# PAC52XX register map
Vendor: Active-Semi; Series: PAC52XX; File version: 1.0
CPU: CM0 r0p0, little endian, no MPU, no FPU, vendor SysTick, 2 interrupt priority bits
Registers are 32-bit, read-write, reset 0x0 unless marked. A register's access mark holds for its fields unless they carry their own. Offsets are from the block's base; [hi:lo] are bit positions.

## I2C
Base 0x401B0000
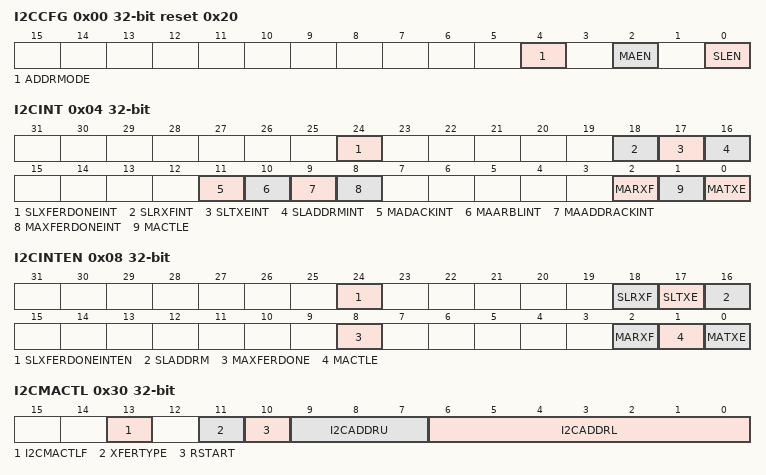
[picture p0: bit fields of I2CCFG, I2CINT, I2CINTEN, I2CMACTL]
0x00 I2CCFG reset 0x20 — I2C Configuration Register
  [4] ADDRMODE — Address Mode
    0=7-bit addressing; 1=10-bit addressing
  [2] MAEN — Master Enable
    0=disable (I2C master disable); 1=enable (I2C Master enable)
  [0] SLEN — Slave Enable
    0=disable (I2C Slave disable); 1=enable (I2C Slave enable)
0x04 I2CINT ro — I2C Interrupt
  [24] SLXFERDONEINT — Slave transfer done interrupt
    0=false (Slave transfer not completed); 1=true (Slave transfer complete, cleared on read)
  [18] SLRXFINT — Slave receive data register SLRXDATA full
    0=false (SLRXDATA did not receive data since last read of I2CINT); 1=true (SLRXDATA received data from I2C bus, cleared on read)
  [17] SLTXEINT — Slave transmit data register SLTXDATA empty
    0=false (SLTXDATA not transmitted since last read of I2CINT); 1=true (SLTXDATA transmitted to I2C bus, cleared on read)
  [16] SLADDRMINT — Slave address match
    0=none (no match); 1=match (Slave address match detected, cleared on read)
  [11] MADACKINT — Master data acknowledge
    0=ACK (Master data ACK'd); 1=NACK (Master data NACK'd, cleared on read)
  [10] MAARBLINT — Master lost arbitration
    0=false (no error); 1=true (Master lost arbitration, clear on read)
  [9] MAADDRACKINT — Master address acknowledged
    0=ACK (Master address ACK'd); 1=NACK (Master address NACK'd, cleared on read)
  [8] MAXFERDONEINT — Master transfer complete
    0=false (not done); 1=true (Master transfer complete, cleared on read)
  [2] MARXF — Master receive data register MARXDATA full
    0=false (MARXDATA did not receive data since last read of I2CINT); 1=true (MARXDATA received data from I2C bus, cleared on read)
  [1] MACTLE — MACCTL access register accessed
    0=false (I2CMACTL not accessed by I2C engine since last read of I2CINT); 1=true (I2CMACTL processed by I2C engine, clears on read)
  [0] MATXE — Master transmit data register MATXDATA empty
    0=not transmitted (MATXDATA not transmitted since last read of I2CINT); 1=transmitted (MATXDATA transmitted to I2C bus, clears on read)
0x08 I2CINTEN — I2C Interrupt Enable
  [all] fields
    0=disabled (interrupt disabled); 1=enabled (interrupt enabled)
  [24] SLXFERDONEINTEN — SLXFERDONEINTEN interrupt enable
  [18] SLRXF — SLRXF interrupt enable
  [17] SLTXE — SLTXE interrupt enable
  [16] SLADDRM — SLADDRM interrupt enable
  [8] MAXFERDONE — MAXFERDONE interrupt enable
  [2] MARXF — MARXF interrupt enable
  [1] MACTLE — MACTLE interrupt enable
  [0] MATXE — MATXE interrupt enable
0x30 I2CMACTL — I2C master access control
  [13] I2CMACTLF — I2CMACTL full
    0=not full (I2CMACTL processed, write allowed); 1=full (I2CMACTL full, write not allowed, cleared on read)
  [11] XFERTYPE — Master transfer type
    0=write (I2C Master write); 1=read (I2C Master read)
  [10] RSTART — Repeated start
    0=no (STOP at end of transfer); 1=yes (No STOP at end of transfer, repeated START)
  [9:7] I2CADDRU — Upper I2C address bits 9:7
  [6:0] I2CADDRL — Lower I2C address bits 6:0
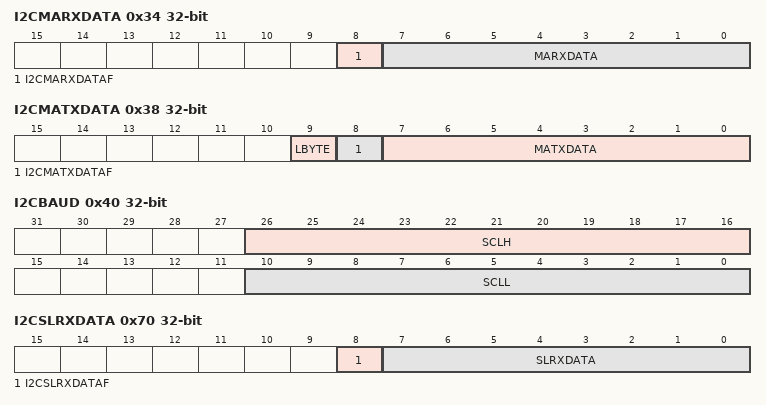
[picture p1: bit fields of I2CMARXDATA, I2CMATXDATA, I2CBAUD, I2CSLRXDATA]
0x34 I2CMARXDATA — I2C master receive data
  [8] I2CMARXDATAF ro — I2CMARXDATA full
    0=empty (I2CMARXDATA register empty); 1=full (I2CMARXDATA register full, cleared on read)
  [7:0] MARXDATA — Master data byte received
0x38 I2CMATXDATA — I2C master transmit data
  [9] LBYTE — Last byte of transfer
    0=false (not last byte of transfer); 1=true (last byte of READ or WRITE indicator, initiate STOP after data transfer)
  [8] I2CMATXDATAF ro — I2CMATXDATA full
    0=empty (I2CMATXDATA register empty); 1=full (I2CMATXDATA register full, cleared on read)
  [7:0] MATXDATA — Master data byte to transmit
0x40 I2CBAUD — I2C baud rate
  [26:16] SCLH — Number of HCLK cycles for I2CCCL high time
  [10:0] SCLL — Number of HCLK cycles for I2CCL low time
0x70 I2CSLRXDATA — I2C slave receive data
  [8] I2CSLRXDATAF ro — I2CSLRXDATA full
    0=empty (I2CSLRXDATA register empty); 1=full (I2CSLRXDATA register full, data not transmitted)
  [7:0] SLRXDATA — Slave data byte received
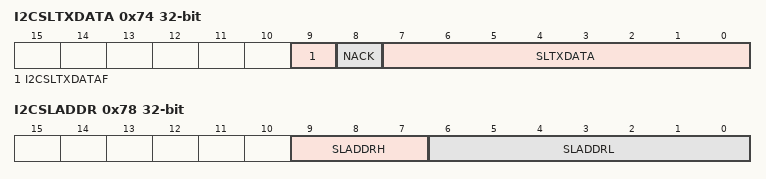
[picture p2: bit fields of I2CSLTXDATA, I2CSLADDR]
0x74 I2CSLTXDATA — I2C slave receive data
  [9] I2CSLTXDATAF ro — I2CSLTXDATA full
    0=empty (I2CSLTXDATA register empty); 1=full (I2CSLTXDATA register full, data not transmitted)
  [8] NACK — Slave ACK or NACK
    0=ACK (Issue ACK on I2C write); 1=NACK (Issue NACK on I2C write)
  [7:0] SLTXDATA — Slave data byte to transmit
0x78 I2CSLADDR — I2C slave address
  [9:7] SLADDRH — Higher slave address bits9:7
  [6:0] SLADDRL — Lower slave address bits 6:0
